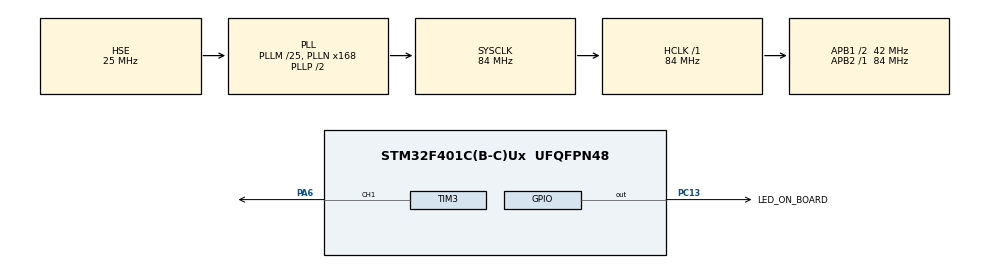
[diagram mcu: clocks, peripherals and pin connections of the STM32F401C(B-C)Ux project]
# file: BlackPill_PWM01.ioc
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Mcu.Family=STM32F4
Mcu.Name=STM32F401C(B-C)Ux
Mcu.Package=UFQFPN48
NVIC.PriorityGroup=NVIC_PRIORITYGROUP_4
PA13.Mode=Serial_Wire
PA13.Signal=SYS_JTMS-SWDIO
PA14.Mode=Serial_Wire
PA14.Signal=SYS_JTCK-SWCLK
PA6.Signal=S_TIM3_CH1
PC13-ANTI_TAMP.GPIO_Label=LED_ON_BOARD
PC13-ANTI_TAMP.Signal=GPIO_Output
PC14-OSC32_IN.Mode=LSE-External-Oscillator
PC14-OSC32_IN.Signal=RCC_OSC32_IN
PC15-OSC32_OUT.Mode=LSE-External-Oscillator
PC15-OSC32_OUT.Signal=RCC_OSC32_OUT
PH0\ -\ OSC_IN.Mode=HSE-External-Oscillator
PH0\ -\ OSC_IN.Signal=RCC_OSC_IN
PH1\ -\ OSC_OUT.Mode=HSE-External-Oscillator
PH1\ -\ OSC_OUT.Signal=RCC_OSC_OUT
ProjectManager.HeapSize=0x200
ProjectManager.StackSize=0x400
ProjectManager.TargetToolchain=STM32CubeIDE
RCC.48MHZClocksFreq_Value=42000000
RCC.AHBFreq_Value=84000000
RCC.APB1CLKDivider=RCC_HCLK_DIV2
RCC.APB1Freq_Value=42000000
RCC.APB1TimFreq_Value=84000000
RCC.APB2Freq_Value=84000000
RCC.APB2TimFreq_Value=84000000
RCC.CortexFreq_Value=84000000
RCC.HCLKFreq_Value=84000000
RCC.HSE_VALUE=25000000
RCC.HSI_VALUE=16000000
RCC.PLLM=25
RCC.PLLN=168
RCC.PLLSourceVirtual=RCC_PLLSOURCE_HSE
RCC.SYSCLKFreq_VALUE=84000000
RCC.SYSCLKSource=RCC_SYSCLKSOURCE_PLLCLK
RCC.VCOOutputFreq_Value=168000000
SH.S_TIM3_CH1.0=TIM3_CH1,PWM Generation1 CH1
TIM3.AutoReloadPreload=TIM_AUTORELOAD_PRELOAD_ENABLE
TIM3.Channel-PWM\ Generation1\ CH1=TIM_CHANNEL_1
TIM3.Prescaler=8399
VP_TIM3_VS_ClockSourceINT.Mode=Internal
board=custom

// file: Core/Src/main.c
/* USER CODE BEGIN Header */
/**
  ******************************************************************************
  * @file           : main.c
  * @brief          : Main program body
  ******************************************************************************
  * @attention
  *
  * Copyright (c) 2025 STMicroelectronics.
  * All rights reserved.
  *
  * This software is licensed under terms that can be found in the LICENSE file
  * in the root directory of this software component.
  * If no LICENSE file comes with this software, it is provided AS-IS.
  *
  ******************************************************************************
  */
/* USER CODE END Header */
#include "main.h"

/* USER CODE BEGIN Includes */
//#include "stm32f4xx_hal.h" // O la familia que uses (f1xx, l4xx, etc.) ya está incluido en main.h

#include "PWM.h"

/* USER CODE END Includes */

TIM_HandleTypeDef htim3;

/* USER CODE BEGIN PV */

// Globales para Live Expressions
uint16_t pwm_periodo_objetivo = 100; // 100ms por defecto
float pwm_duty_objetivo = 50.0f;     // 50% por defecto

/* USER CODE END PV */

void SystemClock_Config(void);
static void MX_GPIO_Init(void);
static void MX_TIM3_Init(void);

int main(void)
{

  /* MCU Configuration--------------------------------------------------------*/

  /* Reset of all peripherals, Initializes the Flash interface and the Systick. */
  HAL_Init();

  /* Configure the system clock */
  SystemClock_Config();

  /* Initialize all configured peripherals */
  MX_GPIO_Init();
  MX_TIM3_Init();
  /* USER CODE BEGIN 2 */

  // ¡Importante! Sin esto el pin no sacará señal
  HAL_TIM_PWM_Start(&htim3, TIM_CHANNEL_1);

  /* USER CODE END 2 */

  /* Infinite loop */
  /* USER CODE BEGIN WHILE */
  while (1)
  {
	 HAL_GPIO_TogglePin(LED_ON_BOARD_GPIO_Port, LED_ON_BOARD_Pin);
//	 HAL_Delay(500);

	 // La función se ejecuta constantemente con los valores de las globales
	 Ajustar_PWM(pwm_periodo_objetivo, pwm_duty_objetivo);
	 HAL_Delay(1000);

    /* USER CODE END WHILE */

  }
}

void SystemClock_Config(void)
{
  RCC_OscInitTypeDef RCC_OscInitStruct = {0};
  RCC_ClkInitTypeDef RCC_ClkInitStruct = {0};

  /** Configure the main internal regulator output voltage
  */
  __HAL_RCC_PWR_CLK_ENABLE();
  __HAL_PWR_VOLTAGESCALING_CONFIG(PWR_REGULATOR_VOLTAGE_SCALE2);

  /** Initializes the RCC Oscillators according to the specified parameters
  * in the RCC_OscInitTypeDef structure.
  */
  RCC_OscInitStruct.OscillatorType = RCC_OSCILLATORTYPE_HSE;
  RCC_OscInitStruct.HSEState = RCC_HSE_ON;
  RCC_OscInitStruct.PLL.PLLState = RCC_PLL_ON;
  RCC_OscInitStruct.PLL.PLLSource = RCC_PLLSOURCE_HSE;
  RCC_OscInitStruct.PLL.PLLM = 25;
  RCC_OscInitStruct.PLL.PLLN = 168;
  RCC_OscInitStruct.PLL.PLLP = RCC_PLLP_DIV2;
  RCC_OscInitStruct.PLL.PLLQ = 4;
  if (HAL_RCC_OscConfig(&RCC_OscInitStruct) != HAL_OK)
  {
    Error_Handler();
  }

  /** Initializes the CPU, AHB and APB buses clocks
  */
  RCC_ClkInitStruct.ClockType = RCC_CLOCKTYPE_HCLK|RCC_CLOCKTYPE_SYSCLK
                              |RCC_CLOCKTYPE_PCLK1|RCC_CLOCKTYPE_PCLK2;
  RCC_ClkInitStruct.SYSCLKSource = RCC_SYSCLKSOURCE_PLLCLK;
  RCC_ClkInitStruct.AHBCLKDivider = RCC_SYSCLK_DIV1;
  RCC_ClkInitStruct.APB1CLKDivider = RCC_HCLK_DIV2;
  RCC_ClkInitStruct.APB2CLKDivider = RCC_HCLK_DIV1;

  if (HAL_RCC_ClockConfig(&RCC_ClkInitStruct, FLASH_LATENCY_2) != HAL_OK)
  {
    Error_Handler();
  }
}

static void MX_TIM3_Init(void)
{

  TIM_ClockConfigTypeDef sClockSourceConfig = {0};
  TIM_MasterConfigTypeDef sMasterConfig = {0};
  TIM_OC_InitTypeDef sConfigOC = {0};

  htim3.Instance = TIM3;
  htim3.Init.Prescaler = 8399;
  htim3.Init.CounterMode = TIM_COUNTERMODE_UP;
  htim3.Init.Period = 65535;
  htim3.Init.ClockDivision = TIM_CLOCKDIVISION_DIV1;
  htim3.Init.AutoReloadPreload = TIM_AUTORELOAD_PRELOAD_ENABLE;
  if (HAL_TIM_Base_Init(&htim3) != HAL_OK)
  {
    Error_Handler();
  }
  sClockSourceConfig.ClockSource = TIM_CLOCKSOURCE_INTERNAL;
  if (HAL_TIM_ConfigClockSource(&htim3, &sClockSourceConfig) != HAL_OK)
  {
    Error_Handler();
  }
  if (HAL_TIM_PWM_Init(&htim3) != HAL_OK)
  {
    Error_Handler();
  }
  sMasterConfig.MasterOutputTrigger = TIM_TRGO_RESET;
  sMasterConfig.MasterSlaveMode = TIM_MASTERSLAVEMODE_DISABLE;
  if (HAL_TIMEx_MasterConfigSynchronization(&htim3, &sMasterConfig) != HAL_OK)
  {
    Error_Handler();
  }
  sConfigOC.OCMode = TIM_OCMODE_PWM1;
  sConfigOC.Pulse = 0;
  sConfigOC.OCPolarity = TIM_OCPOLARITY_HIGH;
  sConfigOC.OCFastMode = TIM_OCFAST_DISABLE;
  if (HAL_TIM_PWM_ConfigChannel(&htim3, &sConfigOC, TIM_CHANNEL_1) != HAL_OK)
  {
    Error_Handler();
  }
  HAL_TIM_MspPostInit(&htim3);

}

static void MX_GPIO_Init(void)
{
  GPIO_InitTypeDef GPIO_InitStruct = {0};

  /* GPIO Ports Clock Enable */
  __HAL_RCC_GPIOC_CLK_ENABLE();
  __HAL_RCC_GPIOH_CLK_ENABLE();
  __HAL_RCC_GPIOA_CLK_ENABLE();

  /*Configure GPIO pin Output Level */
  HAL_GPIO_WritePin(LED_ON_BOARD_GPIO_Port, LED_ON_BOARD_Pin, GPIO_PIN_RESET);

  /*Configure GPIO pin : LED_ON_BOARD_Pin */
  GPIO_InitStruct.Pin = LED_ON_BOARD_Pin;
  GPIO_InitStruct.Mode = GPIO_MODE_OUTPUT_PP;
  GPIO_InitStruct.Pull = GPIO_NOPULL;
  GPIO_InitStruct.Speed = GPIO_SPEED_FREQ_LOW;
  HAL_GPIO_Init(LED_ON_BOARD_GPIO_Port, &GPIO_InitStruct);

}

void Error_Handler(void)
{
  __disable_irq();
  while (1)
  {
  }
}
